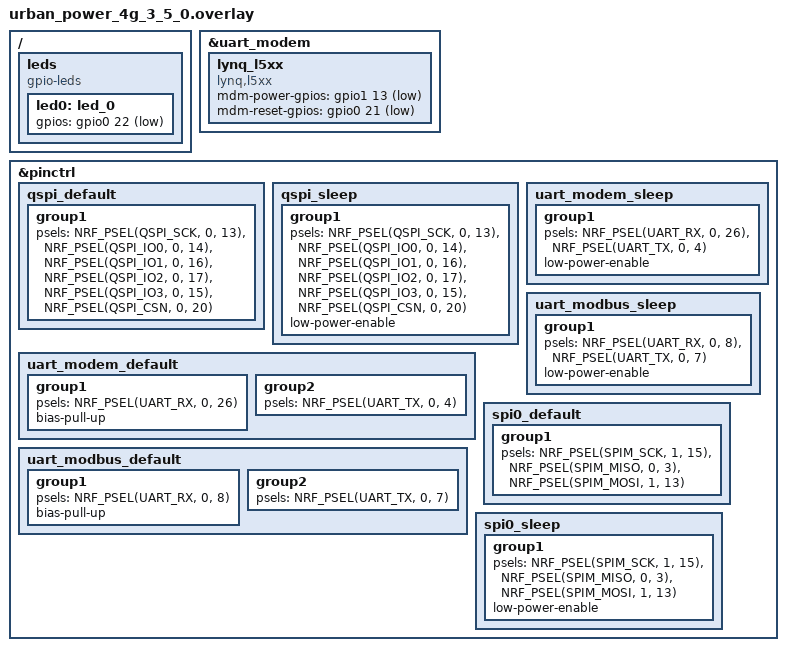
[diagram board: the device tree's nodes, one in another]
/ {
	leds {
		compatible = "gpio-leds";
		led0: led_0 {
			gpios = < &gpio0 22 GPIO_ACTIVE_LOW>;
		};
	};
};

&uart_modem {
	/* Lynq l5xx */
	lynq_l5xx: lynq_l5xx {
		compatible = "lynq,l5xx";
		mdm-power-gpios = <&gpio1 13 GPIO_ACTIVE_LOW>;
		mdm-reset-gpios = <&gpio0 21 GPIO_ACTIVE_LOW>; 
		status = "okay";
	};
};

&pinctrl {
    qspi_default: qspi_default {
		group1 {
			psels = <NRF_PSEL(QSPI_SCK, 0, 13)>,
				<NRF_PSEL(QSPI_IO0, 0, 14)>,
				<NRF_PSEL(QSPI_IO1, 0, 16)>,
				<NRF_PSEL(QSPI_IO2, 0, 17)>,
				<NRF_PSEL(QSPI_IO3, 0, 15)>,
				<NRF_PSEL(QSPI_CSN, 0, 20)>;
		};
	};

	qspi_sleep: qspi_sleep {
		group1 {
			psels = <NRF_PSEL(QSPI_SCK, 0, 13)>,
				<NRF_PSEL(QSPI_IO0, 0, 14)>,
				<NRF_PSEL(QSPI_IO1, 0, 16)>,
				<NRF_PSEL(QSPI_IO2, 0, 17)>,
				<NRF_PSEL(QSPI_IO3, 0, 15)>,
				<NRF_PSEL(QSPI_CSN, 0, 20)>;
			low-power-enable;
		};
	};

	uart_modem_default: uart_modem_default {
		group1 {
			psels = <NRF_PSEL(UART_RX, 0, 26)>;
			bias-pull-up;
		};
		group2 {
			psels = <NRF_PSEL(UART_TX, 0, 4)>;
		};
	};

	uart_modem_sleep: uart_modem_sleep {
		group1 {
			psels = <NRF_PSEL(UART_RX, 0, 26)>,
				<NRF_PSEL(UART_TX, 0, 4)>;
			low-power-enable;
		};
	};

	uart_modbus_default: uart_modbus_default {
		group1 {
			psels = <NRF_PSEL(UART_RX, 0, 8)>;
			bias-pull-up;
		};
		group2 {
			psels = <NRF_PSEL(UART_TX, 0, 7)>;
		};
	};

	uart_modbus_sleep: uart_modbus_sleep {
		group1 {
			psels = <NRF_PSEL(UART_RX, 0, 8)>,
				<NRF_PSEL(UART_TX, 0, 7)>;
			low-power-enable;
		};
	};

	spi0_default: spi0_default {
		group1 {
			psels = <NRF_PSEL(SPIM_SCK, 1, 15)>,
					  <NRF_PSEL(SPIM_MISO, 0, 3)>,
					  <NRF_PSEL(SPIM_MOSI, 1, 13)>;
		};
	};
	
	spi0_sleep: spi0_sleep {
		group1 {
			psels = <NRF_PSEL(SPIM_SCK, 1, 15)>,
					  <NRF_PSEL(SPIM_MISO, 0, 3)>,
					  <NRF_PSEL(SPIM_MOSI, 1, 13)>;
			low-power-enable;
		};
	};
};
